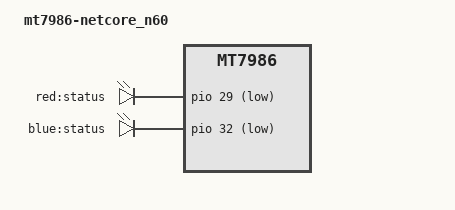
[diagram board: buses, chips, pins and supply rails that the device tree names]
// SPDX-License-Identifier: GPL-2.0

/dts-v1/;
#include "mt7986a-netcore-n60.dtsi"

/ {
	model = "mt7986-netcore_n60";
	compatible = "mediatek,mt7986", "mediatek,mt7986-rfb";

	config {
		blink_led = "blue:status";
		system_led = "red:status";
	};

	gpio-leds {
		compatible = "gpio-leds";

		led_status_red: led-0 {
			label = "red:status";
			gpios = <&pio 29 GPIO_ACTIVE_LOW>;
		};

		led_status_blue: led-1 {
			label = "blue:status";
			gpios = <&pio 32 GPIO_ACTIVE_LOW>;
		};
	};
};
